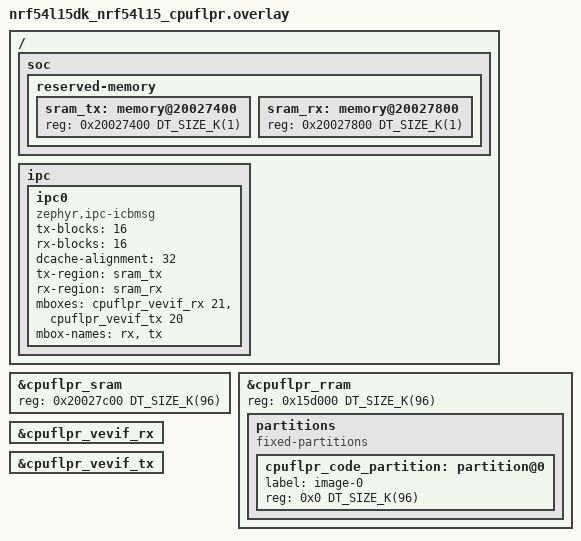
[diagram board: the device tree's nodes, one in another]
/*
 * Copyright (c) 2026 Nordic Semiconductor ASA
 *
 * SPDX-License-Identifier: Apache-2.0
 */

/ {
	soc {
		reserved-memory {
			#address-cells = <1>;
			#size-cells = <1>;

			sram_tx: memory@20027400 {
				reg = <0x20027400 DT_SIZE_K(1)>;
			};

			sram_rx: memory@20027800 {
				reg = <0x20027800 DT_SIZE_K(1)>;
			};
		};
	};

	ipc {
		ipc0: ipc0 {
			compatible = "zephyr,ipc-icbmsg";
			tx-blocks = <16>;
			rx-blocks = <16>;
			dcache-alignment = <32>;
			tx-region = <&sram_tx>;
			rx-region = <&sram_rx>;
			mboxes = <&cpuflpr_vevif_rx 21>, <&cpuflpr_vevif_tx 20>;
			mbox-names = "rx", "tx";
			status = "okay";
		};
	};
};

&cpuflpr_sram {
	reg = <0x20027c00 DT_SIZE_K(96)>;
	ranges = <0x0 0x20027c00 DT_SIZE_K(96)>;
};

&cpuflpr_rram {
	reg = <0x15d000 DT_SIZE_K(96)>;
	ranges = <0x0 0x15d000 DT_SIZE_K(96)>;

	partitions {
		compatible = "fixed-partitions";
		#address-cells = <1>;
		#size-cells = <1>;
		ranges;

		cpuflpr_code_partition: partition@0 {
			label = "image-0";
			reg = <0x0 DT_SIZE_K(96)>;
		};
	};
};

&cpuflpr_vevif_rx {
	status = "okay";
};

&cpuflpr_vevif_tx {
	status = "okay";
};
